# MLDR187 register map
File version: 1.4
CPU: MDR32F02, little endian
Registers are 32-bit, read-write, no defined reset value unless marked. A register's access mark holds for its fields unless they carry their own. Offsets are from the block's base; [hi:lo] are bit positions; {n}, {i} and the like mark numbered series.

## WWDG — WWDG description
Base 0x40048000
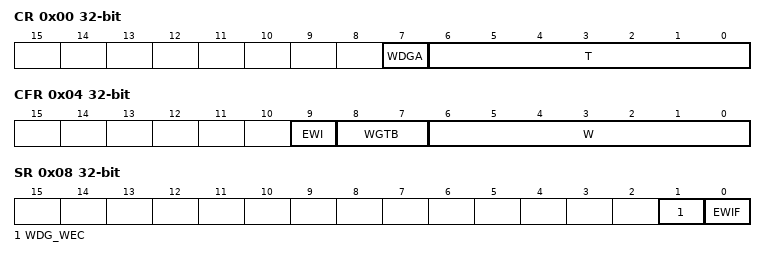
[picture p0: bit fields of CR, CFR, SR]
0x00 CR — CR description
  [7] WDGA — WDGA description
  [6:0] T — T description
0x04 CFR — CFR description
  [9] EWI — EWI description
  [8:7] WGTB — WGTB description
  [6:0] W — W description
0x08 SR — SR description
  [1] WDG_WEC — WDG_WEC description
  [0] EWIF — EWIF description

## IWDG — IWDG description
Base 0x40050000
0x00 KR — KR description
  [15:0] KEY — KEY description
0x04 PR — PR description
  [2:0] PR
0x08 RLR — RLR description
  [11:0] RLR
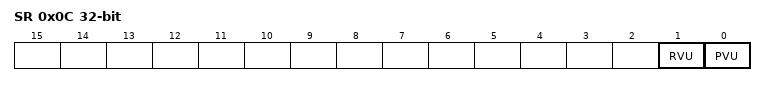
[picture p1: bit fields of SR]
0x0C SR — SR description
  [1] RVU — RVU description
  [0] PVU — PVU description

## ISO7816 — ISO7816 description
Base 0x400C0000
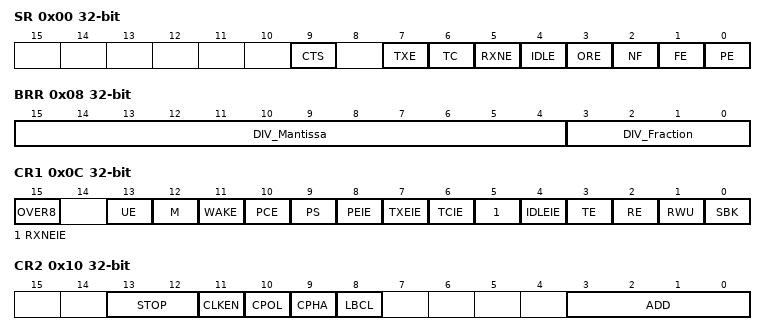
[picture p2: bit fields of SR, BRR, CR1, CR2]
0x00 SR — Status register
  [9] CTS — CTS flag
  [7] TXE — TX empty
  [6] TC — Transmit complete
  [5] RXNE — Read data register not empty
  [4] IDLE — IDLE line detected
  [3] ORE — Overrun error
  [2] NF — Noise error flag
  [1] FE — Frame error
  [0] PE — Parity error
0x04 DR — Data register
  [8:0] DR
0x08 BRR — Baud rate register
  [15:4] DIV_Mantissa, [3:0] DIV_Fraction
0x0C CR1 — Control register 1
  [15] OVER8 — Oversampling mode
  [13] UE — USART Enable
  [12] M — Byte len. 1 - 9;0 - 8
  [11] WAKE — Wake bit
  [10] PCE — Parity control enable
  [9] PS — Parity selection
  [8] PEIE — PE interrupt enable
  [7] TXEIE — TXE interrupt enable
  [6] TCIE — Transmission complete interrupt enable
  [5] RXNEIE — RXNE interrupt enable
  [4] IDLEIE — IDLE interrupt enable
  [3] TE — Transmitter enable
  [2] RE — Receiver enable
  [1] RWU — Receiver wakeup
  [0] SBK — Send break
0x10 CR2 — Control register 2
  [13:12] STOP — Stop bit type mask
  [11] CLKEN — Clock enable
  [10] CPOL — Clock polarity
  [9] CPHA — Clock phase
  [8] LBCL — Last bit clock pulse
  [3:0] ADD — Address of the USART node
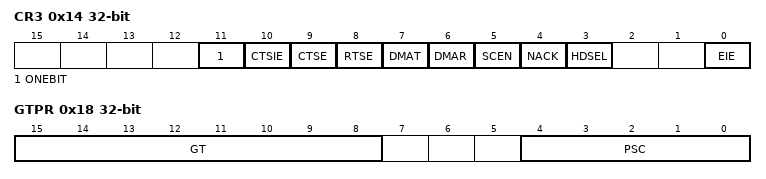
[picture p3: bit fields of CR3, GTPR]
0x14 CR3 — Control register 3
  [11] ONEBIT — One sample per bit mode resolution
  [10] CTSIE — CTS interrupt enable
  [9] CTSE — CTS enable
  [8] RTSE — RTS enable
  [7] DMAT — DMA enable transmitter
  [6] DMAR — DMA enable receiver
  [5] SCEN — Smartcard mode enable
  [4] NACK — Smartcard NACK
  [3] HDSEL — Half-duplex selection
  [0] EIE — Error interrupt enable
0x18 GTPR — Guard time and prescaler register
  [15:8] GT — GT description
  [4:0] PSC — PSC description

## PBYTE — PBYTE description
Base 0x60028000
{0x0+4i} TRM_{i:02} (i=0..15) — Transformation register {i}
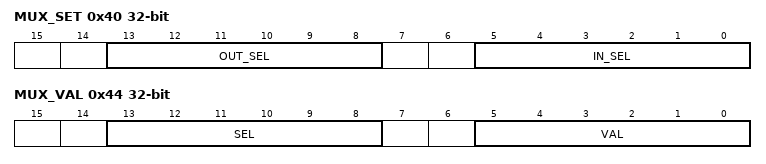
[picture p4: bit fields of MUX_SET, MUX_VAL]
0x40 MUX_SET — Transformation setup register
  [13:8] OUT_SEL wo — OUT_SEL description
  [5:0] IN_SEL wo — IN_SEL description
0x44 MUX_VAL — Transformation value register
  [13:8] SEL wo — SEL description
  [5:0] VAL ro — VAL description

## SBLOCK0 — SBLOCK0 description
Base 0x60008000
Same registers: SBLOCK1 0x6000C000, SBLOCK2 0x60010000, SBLOCK3 0x60014000, SBLOCK4 0x60018000, SBLOCK5 0x6001C000, SBLOCK6 0x60020000, SBLOCK7 0x60024000
{0x0+4i} TRM_{i:02} (i=0..3) — Transformation register {i}
{0x0+4i} TRM_{i:02} (i=4..7) — Transformation register {i-4}
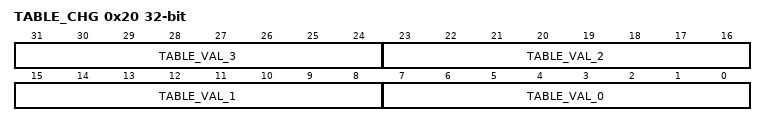
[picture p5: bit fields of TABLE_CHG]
0x20 TABLE_CHG — Table change register
  [8n+7:8n] TABLE_VAL_{n} (n=0..3) — TABLE_VAL_{n} description
0x24 M_SCTRL — Memory special control

## LBLOCK — LBLOCK description
Base 0x60004000
{0x0+4i} TRM_{i:02} (i=0..3) — Transformation register {i}
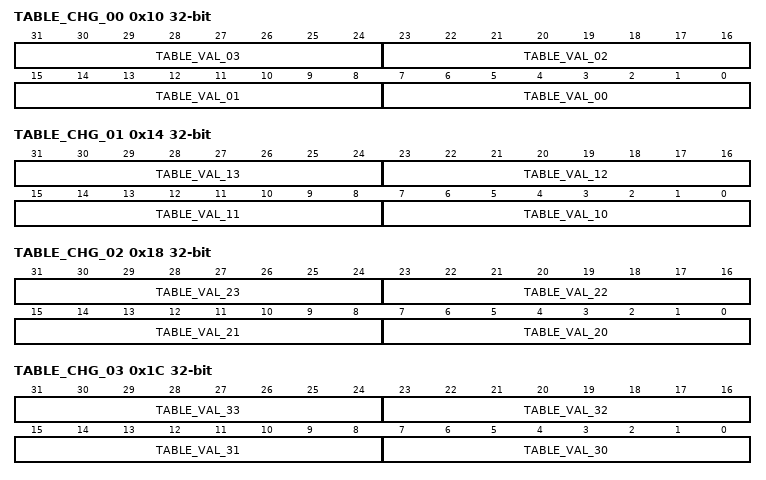
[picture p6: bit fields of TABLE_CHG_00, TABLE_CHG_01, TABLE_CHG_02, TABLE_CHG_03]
0x10 TABLE_CHG_00 — Table change 0 register
  [8n+7:8n] TABLE_VAL_{n:02} (n=0..3) — TABLE_VAL_{n:02} description
0x14 TABLE_CHG_01 — Table change 1 register
  [8n-73:8n-80] TABLE_VAL_{n} (n=10..13) — TABLE_VAL_{n} description
0x18 TABLE_CHG_02 — Table change 2 register
  [8n-153:8n-160] TABLE_VAL_{n} (n=20..23) — TABLE_VAL_{n} description
0x1C TABLE_CHG_03 — Table change 3 register
  [8n-233:8n-240] TABLE_VAL_{n} (n=30..33) — TABLE_VAL_{n} description
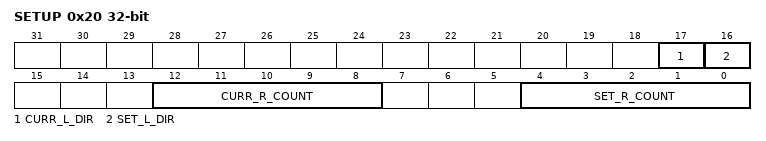
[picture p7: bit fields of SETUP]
0x20 SETUP
  [17] CURR_L_DIR — CURR_L_DIR description
  [16] SET_L_DIR — SET_L_DIR description
  [12:8] CURR_R_COUNT — CURR_R_COUNT description
  [4:0] SET_R_COUNT — SET_R_COUNT description
0x24 M_SCTRL — Memory special control
